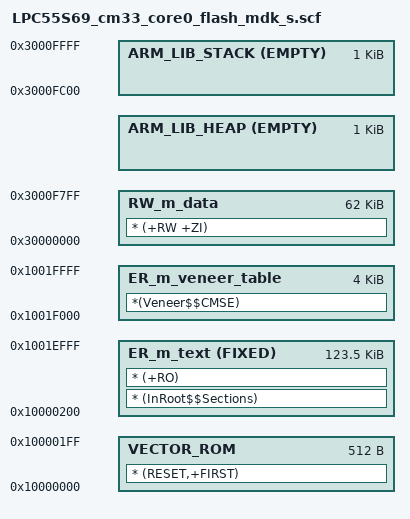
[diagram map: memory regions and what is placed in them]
#!armclang --target=arm-arm-none-eabi -march=armv8-m.main -E -x c
/*
** ###################################################################
**     Processors:          LPC55S69JBD100_cm33_core0
**                          LPC55S69JET98_cm33_core0
**
**     Compiler:            Keil ARM C/C++ Compiler
**     Reference manual:    LPC55xx/LPC55Sxx User manual Rev.0.2  15 Aug 2018
**     Version:             rev. 1.0, 2018-08-22
**     Build:               b181008
**
**     Abstract:
**         Linker file for the Keil ARM C/C++ Compiler
**
**     Copyright 2016 Freescale Semiconductor, Inc.
**     Copyright 2016-2018 NXP
**     All rights reserved.
**
**     SPDX-License-Identifier: BSD-3-Clause
**
**     http:                 www.nxp.com
**     mail:                 support@nxp.com
**
** ###################################################################
*/

/* 128KB Flash for Secure */
/* 64KB  SRAM0 for Secure */

/* USB BDT size */
#define  usb_bdt_size                  0x0
/* Sizes */
#define  Stack_Size                    0x0400
#define  Heap_Size                     0x0400

#define  m_interrupts_start            0x10000000
#define  m_interrupts_size             0x00000200

#define  m_text_start                  0x10000200
#define  m_text_size                   0x0001EE00

#define  m_veneer_table_start          0x1001F000
#define  m_veneer_table_size           0x00001000

#define  m_data_start                  0x30000000
#define  m_data_size                   0x00010000

LR_m_text m_interrupts_start m_interrupts_size+m_text_size {   ; load region size_region

  VECTOR_ROM m_interrupts_start m_interrupts_size { ; load address = execution address
    * (RESET,+FIRST)
  }

  ER_m_text m_text_start FIXED m_text_size { ; load address = execution address
    * (InRoot$$Sections)
    * (+RO)
  }

  RW_m_data m_data_start m_data_size-Stack_Size-Heap_Size { ; RW data
    * (+RW +ZI)
  }
  ARM_LIB_HEAP +0 EMPTY Heap_Size {    ; Heap region growing up
  }
  ARM_LIB_STACK m_data_start+m_data_size EMPTY -Stack_Size { ; Stack region growing down
  }
}

LR_m_veneer_table m_veneer_table_start m_veneer_table_size {
  ER_m_veneer_table m_veneer_table_start m_veneer_table_size {; veneer table
    *(Veneer$$CMSE)
  }
}
